VERSION ""

NS_ :

BS_:

BU_: ControlSwitches DashBoard BCM PWC_Rear PWC_Front

BO_ 1537 BCM_PWC_Control: 3 BCM
 SG_ emergency : 22|1@1+ (1,0) [0|0] ""  PWC_Rear,PWC_Front
 SG_ PassangerCtrl_Rear_R_Up : 21|1@1+ (1,0) [0|0] ""  PWC_Rear
 SG_ PassangerCtrl_Rear_R_Down : 20|1@1+ (1,0) [0|0] ""  PWC_Rear
 SG_ PassangerCtrl_Rear_L_Up : 19|1@1+ (1,0) [0|0] ""  PWC_Rear
 SG_ PassangerCtrl_Rear_L_Down : 18|1@1+ (1,0) [0|0] ""  PWC_Rear
 SG_ PassangerCtrl_Front_R_Up : 17|1@1+ (1,0) [0|0] ""  PWC_Front
 SG_ PassangerCtrl_Front_R_Down : 16|1@1+ (1,0) [0|0] ""  PWC_Front
 SG_ DrvCtrl_Rear_R_Up : 15|1@1+ (1,0) [0|0] ""  PWC_Rear
 SG_ DrvCtrl_Rear_R_Down : 14|1@1+ (1,0) [0|0] ""  PWC_Rear
 SG_ DrvCtrl_Rear_R_Auto : 12|2@1+ (1,0) [0|0] ""  PWC_Rear
 SG_ DrvCtrl_Rear_L_Up : 11|1@1+ (1,0) [0|0] ""  PWC_Rear
 SG_ DrvCtrl_Rear_L_Down : 10|1@1+ (1,0) [0|0] ""  PWC_Rear
 SG_ DrvCtrl_Rear_L_Auto : 8|2@1+ (1,0) [0|0] ""  PWC_Rear
 SG_ DrvCtrl_Front_R_Up : 7|1@1+ (1,0) [0|0] ""  PWC_Front
 SG_ DrvCtrl_Front_R_Down : 6|1@1+ (1,0) [0|0] ""  PWC_Front
 SG_ DrvCtrl_Front_R_Auto : 4|2@1+ (1,0) [0|0] ""  PWC_Front
 SG_ DrvCtrl_Front_L_Up : 3|1@1+ (1,0) [0|0] ""  PWC_Front
 SG_ DrvCtrl_Front_L_Down : 2|1@1+ (1,0) [0|0] ""  PWC_Front
 SG_ DrvCtrl_Front_L_Auto : 0|2@1+ (1,0) [0|0] ""  PWC_Front

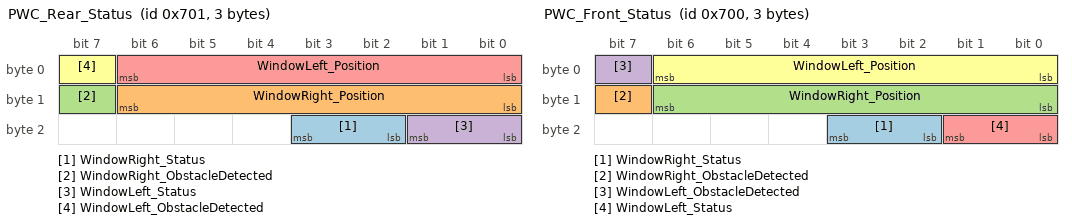
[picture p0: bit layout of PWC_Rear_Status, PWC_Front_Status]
BO_ 1793 PWC_Rear_Status: 3 PWC_Rear
 SG_ WindowRight_Status : 18|2@1+ (1,0) [0|0] ""  BCM
 SG_ WindowRight_Position : 8|7@1+ (1,0) [0|100] ""  BCM
 SG_ WindowRight_ObstacleDetected : 15|1@1+ (1,0) [0|0] ""  BCM
 SG_ WindowLeft_Status : 16|2@1+ (1,0) [0|0] ""  BCM
 SG_ WindowLeft_Position : 0|7@1+ (1,0) [0|100] ""  BCM
 SG_ WindowLeft_ObstacleDetected : 7|1@1+ (1,0) [0|0] ""  BCM

BO_ 1792 PWC_Front_Status: 3 PWC_Front
 SG_ WindowRight_Status : 18|2@1+ (1,0) [0|0] ""  BCM
 SG_ WindowRight_ObstacleDetected : 15|1@1+ (1,0) [0|0] ""  BCM
 SG_ WindowRight_Position : 8|7@1+ (1,0) [0|100] ""  BCM
 SG_ WindowLeft_ObstacleDetected : 7|1@1+ (1,0) [0|0] ""  BCM
 SG_ WindowLeft_Status : 16|2@1+ (1,0) [0|0] ""  BCM
 SG_ WindowLeft_Position : 0|7@1+ (1,0) [0|100] ""  BCM

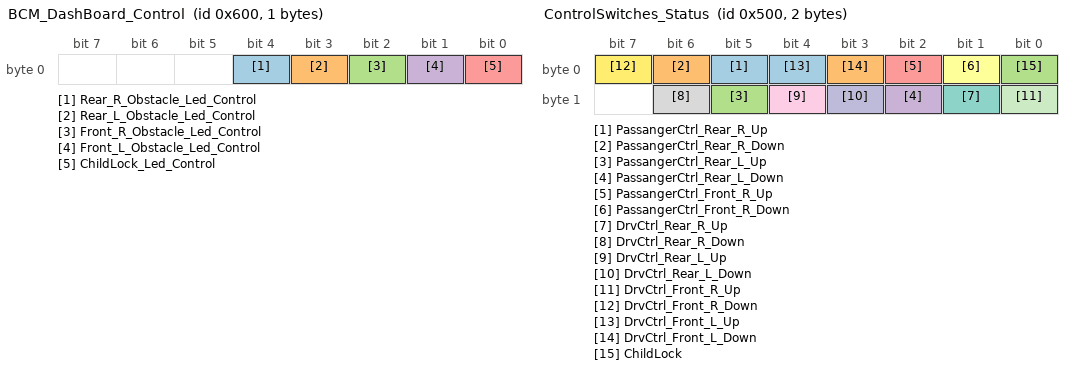
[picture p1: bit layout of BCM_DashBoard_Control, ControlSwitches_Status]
BO_ 1536 BCM_DashBoard_Control: 1 BCM
 SG_ Rear_R_Obstacle_Led_Control : 4|1@1+ (1,0) [0|0] ""  DashBoard
 SG_ Rear_L_Obstacle_Led_Control : 3|1@1+ (1,0) [0|0] ""  DashBoard
 SG_ Front_R_Obstacle_Led_Control : 2|1@1+ (1,0) [0|0] ""  DashBoard
 SG_ Front_L_Obstacle_Led_Control : 1|1@1+ (1,0) [0|0] ""  DashBoard
 SG_ ChildLock_Led_Control : 0|1@1+ (1,0) [0|0] ""  DashBoard

BO_ 1280 ControlSwitches_Status: 2 ControlSwitches
 SG_ PassangerCtrl_Rear_R_Up : 5|1@1+ (1,0) [0|0] ""  BCM
 SG_ PassangerCtrl_Rear_R_Down : 6|1@1+ (1,0) [0|0] ""  BCM
 SG_ PassangerCtrl_Rear_L_Up : 13|1@1+ (1,0) [0|0] ""  BCM
 SG_ PassangerCtrl_Rear_L_Down : 10|1@1+ (1,0) [0|0] ""  BCM
 SG_ PassangerCtrl_Front_R_Up : 2|1@1+ (1,0) [0|0] ""  BCM
 SG_ PassangerCtrl_Front_R_Down : 1|1@1+ (1,0) [0|0] ""  BCM
 SG_ DrvCtrl_Rear_R_Up : 9|1@1+ (1,0) [0|0] ""  BCM
 SG_ DrvCtrl_Rear_R_Down : 14|1@1+ (1,0) [0|0] ""  BCM
 SG_ DrvCtrl_Rear_L_Up : 12|1@1+ (1,0) [0|0] ""  BCM
 SG_ DrvCtrl_Rear_L_Down : 11|1@1+ (1,0) [0|0] ""  BCM
 SG_ DrvCtrl_Front_R_Up : 8|1@1+ (1,0) [0|0] ""  BCM
 SG_ DrvCtrl_Front_R_Down : 7|1@1+ (1,0) [0|0] ""  BCM
 SG_ DrvCtrl_Front_L_Up : 4|1@1+ (1,0) [0|0] ""  BCM
 SG_ DrvCtrl_Front_L_Down : 3|1@1+ (1,0) [0|0] ""  BCM
 SG_ ChildLock : 0|1@1+ (1,0) [0|0] ""  BCM

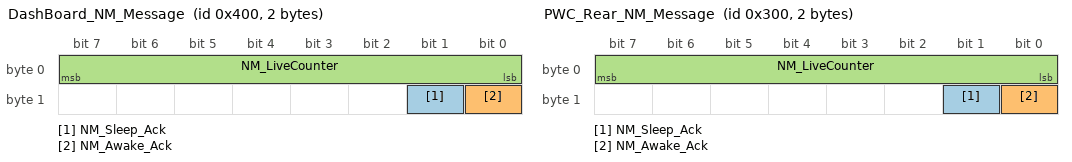
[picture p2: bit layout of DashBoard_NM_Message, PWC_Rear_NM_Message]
BO_ 1024 DashBoard_NM_Message: 2 DashBoard
 SG_ NM_Sleep_Ack : 9|1@1+ (1,0) [0|0] ""  BCM
 SG_ NM_Awake_Ack : 8|1@1+ (1,0) [0|1] ""  BCM
 SG_ NM_LiveCounter : 0|8@1+ (1,0) [0|255] ""  BCM

BO_ 768 PWC_Rear_NM_Message: 2 PWC_Rear
 SG_ NM_Sleep_Ack : 9|1@1+ (1,0) [0|0] ""  BCM
 SG_ NM_Awake_Ack : 8|1@1+ (1,0) [0|1] ""  BCM
 SG_ NM_LiveCounter : 0|8@1+ (1,0) [0|255] ""  BCM

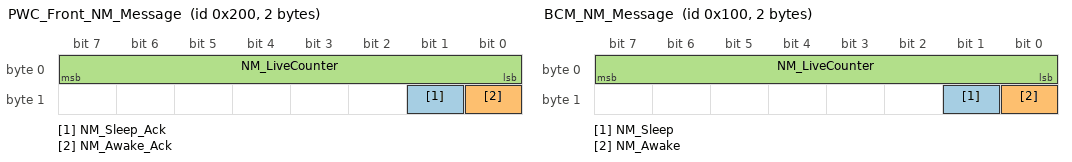
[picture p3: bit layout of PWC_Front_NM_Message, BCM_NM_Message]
BO_ 512 PWC_Front_NM_Message: 2 PWC_Front
 SG_ NM_Sleep_Ack : 9|1@1+ (1,0) [0|0] ""  BCM
 SG_ NM_Awake_Ack : 8|1@1+ (1,0) [0|1] ""  BCM
 SG_ NM_LiveCounter : 0|8@1+ (1,0) [0|255] ""  BCM

BO_ 256 BCM_NM_Message: 2 BCM
 SG_ NM_Sleep : 9|1@1+ (1,0) [0|1] ""  PWC_Rear,DashBoard,PWC_Front
 SG_ NM_Awake : 8|1@1+ (1,0) [0|1] ""  PWC_Rear,DashBoard,PWC_Front
 SG_ NM_LiveCounter : 0|8@1+ (1,0) [0|255] ""  PWC_Rear,DashBoard,PWC_Front

BA_DEF_  "BusType" STRING ;
BA_DEF_DEF_  "BusType" "CAN";
